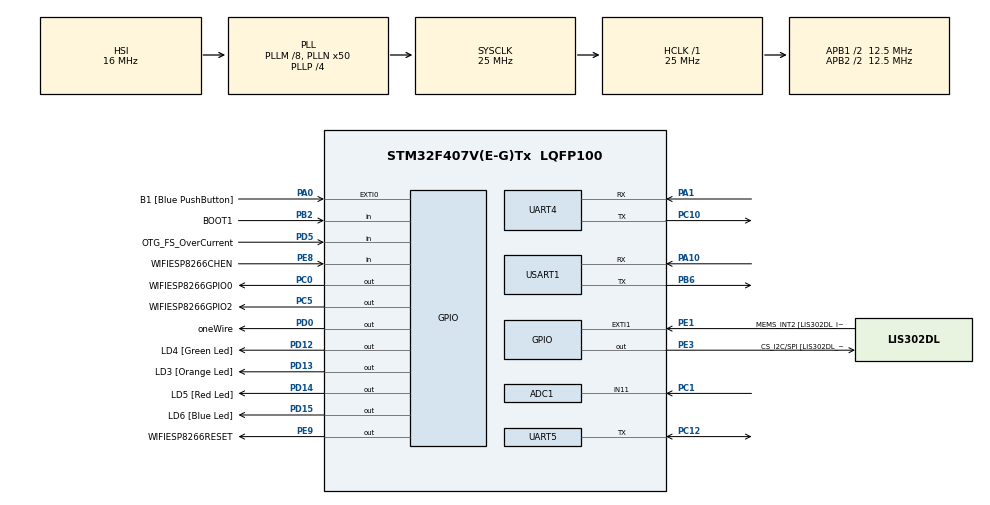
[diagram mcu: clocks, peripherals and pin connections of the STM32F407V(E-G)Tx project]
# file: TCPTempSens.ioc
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ADC1.Channel-0\#ChannelRegularConversion=ADC_CHANNEL_11
ADC1.NbrOfConversionFlag=1
ADC1.Rank-0\#ChannelRegularConversion=1
ADC1.SamplingTime-0\#ChannelRegularConversion=ADC_SAMPLETIME_3CYCLES
ADC1.master=1
Mcu.Family=STM32F4
Mcu.Name=STM32F407V(E-G)Tx
Mcu.Package=LQFP100
NVIC.PriorityGroup=NVIC_PRIORITYGROUP_0
NVIC.TIM1_TRG_COM_TIM11_IRQn=true\:0\:0\:false\:true\:true\:3\:true\:true\:true
NVIC.TIM1_UP_TIM10_IRQn=true\:0\:5\:false\:true\:true\:1\:true\:true\:true
NVIC.UART4_IRQn=true\:0\:5\:false\:true\:true\:2\:true\:true\:true
PA0-WKUP.GPIO_Label=B1 [Blue PushButton]
PA0-WKUP.Signal=GPXTI0
PA1.Mode=Asynchronous
PA1.Signal=UART4_RX
PA10.Mode=Asynchronous
PA10.Signal=USART1_RX
PA13.GPIO_Label=SWDIO
PA13.Mode=Serial_Wire
PA13.Signal=SYS_JTMS-SWDIO
PA14.GPIO_Label=SWCLK
PA14.Mode=Serial_Wire
PA14.Signal=SYS_JTCK-SWCLK
PA9.GPIO_Label=VBUS_FS
PA9.GPIO_Mode=GPIO_MODE_INPUT
PA9.GPIO_PuPd=GPIO_NOPULL
PA9.Signal=USB_OTG_FS_VBUS
PB2.GPIO_Label=BOOT1
PB2.GPIO_Mode=GPIO_MODE_INPUT
PB2.GPIO_PuPd=GPIO_NOPULL
PB2.Signal=GPIO_Input
PB3.GPIO_Label=SWO
PB3.Signal=SYS_JTDO-SWO
PB6.Mode=Asynchronous
PB6.Signal=USART1_TX
PC0.GPIO_Label=WIFIESP8266GPIO0
PC0.GPIO_PuPd=GPIO_PULLUP
PC0.GPIO_Speed=GPIO_SPEED_FREQ_LOW
PC0.PinState=GPIO_PIN_SET
PC0.Signal=GPIO_Output
PC1.Signal=ADCx_IN11
PC10.Mode=Asynchronous
PC10.Signal=UART4_TX
PC12.Mode=Half_duplex(single_wire_mode)
PC12.Signal=UART5_TX
PC14-OSC32_IN.GPIO_Label=PC14-OSC32_IN
PC14-OSC32_IN.Signal=RCC_OSC32_IN
PC15-OSC32_OUT.GPIO_Label=PC15-OSC32_OUT
PC15-OSC32_OUT.Signal=RCC_OSC32_OUT
PC5.GPIO_Label=WIFIESP8266GPIO2
PC5.GPIO_PuPd=GPIO_PULLUP
PC5.PinState=GPIO_PIN_SET
PC5.Signal=GPIO_Output
PD0.GPIO_Label=oneWire
PD0.GPIO_ModeDefaultOutputPP=GPIO_MODE_OUTPUT_OD
PD0.GPIO_PuPd=GPIO_NOPULL
PD0.Signal=GPIO_Output
PD12.GPIO_Label=LD4 [Green Led]
PD12.GPIO_PuPd=GPIO_NOPULL
PD12.GPIO_Speed=GPIO_SPEED_FREQ_LOW
PD12.Signal=GPIO_Output
PD13.GPIO_Label=LD3 [Orange Led]
PD13.GPIO_PuPd=GPIO_NOPULL
PD13.GPIO_Speed=GPIO_SPEED_FREQ_LOW
PD13.Signal=GPIO_Output
PD14.GPIO_Label=LD5 [Red Led]
PD14.GPIO_PuPd=GPIO_NOPULL
PD14.GPIO_Speed=GPIO_SPEED_FREQ_LOW
PD14.Signal=GPIO_Output
PD15.GPIO_Label=LD6 [Blue Led]
PD15.GPIO_PuPd=GPIO_NOPULL
PD15.GPIO_Speed=GPIO_SPEED_FREQ_LOW
PD15.Signal=GPIO_Output
PD5.GPIO_Label=OTG_FS_OverCurrent
PD5.GPIO_Mode=GPIO_MODE_INPUT
PD5.GPIO_PuPd=GPIO_NOPULL
PD5.Signal=GPIO_Input
PE1.GPIO_Label=MEMS_INT2 [LIS302DL_INT2]
PE1.GPIO_ModeDefaultEXTI=GPIO_MODE_EVT_RISING
PE1.GPIO_PuPd=GPIO_NOPULL
PE1.Signal=GPXTI1
PE3.GPIO_Label=CS_I2C/SPI [LIS302DL_CS_I2C/SPI]
PE3.GPIO_PuPd=GPIO_NOPULL
PE3.GPIO_Speed=GPIO_SPEED_FREQ_LOW
PE3.Signal=GPIO_Output
PE8.GPIO_Label=WIFIESP8266CHEN
PE8.GPIO_PuPd=GPIO_PULLUP
PE8.Signal=GPIO_Input
PE9.GPIO_Label=WIFIESP8266RESET
PE9.GPIO_PuPd=GPIO_PULLUP
PE9.Signal=GPIO_Output
PH0-OSC_IN.GPIO_Label=PH0-OSC_IN
PH0-OSC_IN.Signal=RCC_OSC_IN
PH1-OSC_OUT.GPIO_Label=PH1-OSC_OUT
PH1-OSC_OUT.Signal=RCC_OSC_OUT
ProjectManager.HeapSize=0x200
ProjectManager.StackSize=0x400
ProjectManager.TargetToolchain=STM32CubeIDE
RCC.48MHZClocksFreq_Value=14285714.285714285
RCC.AHBFreq_Value=25000000
RCC.APB1CLKDivider=RCC_HCLK_DIV2
RCC.APB1Freq_Value=12500000
RCC.APB1TimFreq_Value=25000000
RCC.APB2CLKDivider=RCC_HCLK_DIV2
RCC.APB2Freq_Value=12500000
RCC.APB2TimFreq_Value=25000000
RCC.CortexFreq_Value=25000000
RCC.HCLKFreq_Value=25000000
RCC.HSE_VALUE=8000000
RCC.HSI_VALUE=16000000
RCC.LSE_VALUE=32768
RCC.PLLM=8
RCC.PLLN=50
RCC.PLLP=RCC_PLLP_DIV4
RCC.PLLQ=7
RCC.SYSCLKFreq_VALUE=25000000
RCC.SYSCLKSource=RCC_SYSCLKSOURCE_PLLCLK
RCC.VCOOutputFreq_Value=100000000
SH.ADCx_IN11.0=ADC1_IN11,IN11
TIM10.Period=24999 
TIM10.Prescaler=0
TIM11.Period=9999
TIM11.Prescaler=2499
UART4.VirtualMode=Asynchronous
UART5.VirtualMode=Asynchronous
USART1.VirtualMode=VM_ASYNC
VP_RTC_VS_RTC_Activate.Mode=RTC_Enabled
VP_RTC_VS_RTC_Calendar.Mode=RTC_Calendar
VP_TIM10_VS_ClockSourceINT.Mode=Enable_Timer
VP_TIM11_VS_ClockSourceINT.Mode=Enable_Timer
board=STM32F407G-DISC1

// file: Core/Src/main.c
/* USER CODE BEGIN Header */
/**
  ******************************************************************************
  * @file           : main.c
  * @brief          : Main program body
  ******************************************************************************
  * @attention
  *
  * Copyright (c) 2022 STMicroelectronics.
  * All rights reserved.
  *
  * This software is licensed under terms that can be found in the LICENSE file
  * in the root directory of this software component.
  * If no LICENSE file comes with this software, it is provided AS-IS.
  *
  ******************************************************************************
  */
/* USER CODE END Header */
#include "main.h"
#include "adc.h"
#include "rtc.h"
#include "tim.h"
#include "usart.h"
#include "gpio.h"

/* USER CODE BEGIN Includes */
#include "NewMain.h"
/* USER CODE END Includes */

void SystemClock_Config(void);
static void MX_NVIC_Init(void);

int main(void)
{

  /* MCU Configuration--------------------------------------------------------*/

  /* Reset of all peripherals, Initializes the Flash interface and the Systick. */
  HAL_Init();

  /* Configure the system clock */
  SystemClock_Config();

  /* Initialize all configured peripherals */
  MX_GPIO_Init();
  MX_ADC1_Init();
  MX_UART4_Init();
  MX_TIM10_Init();
  MX_UART5_Init();
  MX_TIM11_Init();
  MX_USART1_UART_Init();
  MX_RTC_Init();

  /* Initialize interrupts */
  MX_NVIC_Init();
  /* USER CODE BEGIN 2 */
  //HelloWorld();
  newMain();
  /* USER CODE END 2 */

  /* Infinite loop */
  while (1)
  {

  }
}

void SystemClock_Config(void)
{
  RCC_OscInitTypeDef RCC_OscInitStruct = {0};
  RCC_ClkInitTypeDef RCC_ClkInitStruct = {0};

  /** Configure the main internal regulator output voltage
  */
  __HAL_RCC_PWR_CLK_ENABLE();
  __HAL_PWR_VOLTAGESCALING_CONFIG(PWR_REGULATOR_VOLTAGE_SCALE1);
  /** Initializes the RCC Oscillators according to the specified parameters
  * in the RCC_OscInitTypeDef structure.
  */
  RCC_OscInitStruct.OscillatorType = RCC_OSCILLATORTYPE_HSI|RCC_OSCILLATORTYPE_LSI;
  RCC_OscInitStruct.HSIState = RCC_HSI_ON;
  RCC_OscInitStruct.HSICalibrationValue = RCC_HSICALIBRATION_DEFAULT;
  RCC_OscInitStruct.LSIState = RCC_LSI_ON;
  RCC_OscInitStruct.PLL.PLLState = RCC_PLL_ON;
  RCC_OscInitStruct.PLL.PLLSource = RCC_PLLSOURCE_HSI;
  RCC_OscInitStruct.PLL.PLLM = 8;
  RCC_OscInitStruct.PLL.PLLN = 50;
  RCC_OscInitStruct.PLL.PLLP = RCC_PLLP_DIV4;
  RCC_OscInitStruct.PLL.PLLQ = 7;
  if (HAL_RCC_OscConfig(&RCC_OscInitStruct) != HAL_OK)
  {
    Error_Handler();
  }
  /** Initializes the CPU, AHB and APB buses clocks
  */
  RCC_ClkInitStruct.ClockType = RCC_CLOCKTYPE_HCLK|RCC_CLOCKTYPE_SYSCLK
                              |RCC_CLOCKTYPE_PCLK1|RCC_CLOCKTYPE_PCLK2;
  RCC_ClkInitStruct.SYSCLKSource = RCC_SYSCLKSOURCE_PLLCLK;
  RCC_ClkInitStruct.AHBCLKDivider = RCC_SYSCLK_DIV1;
  RCC_ClkInitStruct.APB1CLKDivider = RCC_HCLK_DIV2;
  RCC_ClkInitStruct.APB2CLKDivider = RCC_HCLK_DIV2;

  if (HAL_RCC_ClockConfig(&RCC_ClkInitStruct, FLASH_LATENCY_0) != HAL_OK)
  {
    Error_Handler();
  }
}

/**
  * @brief NVIC Configuration.
  * @retval None
  */
static void MX_NVIC_Init(void)
{
  /* TIM1_UP_TIM10_IRQn interrupt configuration */
  HAL_NVIC_SetPriority(TIM1_UP_TIM10_IRQn, 0, 5);
  HAL_NVIC_EnableIRQ(TIM1_UP_TIM10_IRQn);
  /* UART4_IRQn interrupt configuration */
  HAL_NVIC_SetPriority(UART4_IRQn, 0, 5);
  HAL_NVIC_EnableIRQ(UART4_IRQn);
  /* TIM1_TRG_COM_TIM11_IRQn interrupt configuration */
  HAL_NVIC_SetPriority(TIM1_TRG_COM_TIM11_IRQn, 0, 0);
  HAL_NVIC_EnableIRQ(TIM1_TRG_COM_TIM11_IRQn);
}

void Error_Handler(void)
{
  __disable_irq();
  while (1)
  {
  }
}
